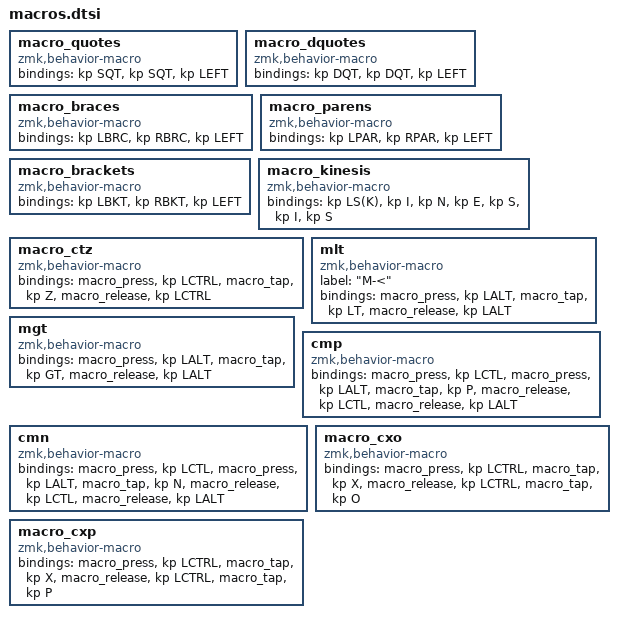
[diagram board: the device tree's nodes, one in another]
  macro_quotes: macro_quotes {
    compatible = "zmk,behavior-macro";
    #binding-cells = <0>;
    bindings = <&kp SQT>, <&kp SQT>, <&kp LEFT>;
  };
  macro_dquotes: macro_dquotes {
    compatible = "zmk,behavior-macro";
    #binding-cells = <0>;
    bindings = <&kp DQT>, <&kp DQT>, <&kp LEFT>;
  };
  macro_braces: macro_braces {
    compatible = "zmk,behavior-macro";
    #binding-cells = <0>;
    bindings = <&kp LBRC>, <&kp RBRC>, <&kp LEFT>;
  };
  macro_parens: macro_parens {
    compatible = "zmk,behavior-macro";
    #binding-cells = <0>;
    bindings = <&kp LPAR>, <&kp RPAR>, <&kp LEFT>;
  };
  macro_brackets: macro_brackets {
    compatible = "zmk,behavior-macro";
    #binding-cells = <0>;
    bindings = <&kp LBKT>, <&kp RBKT>, <&kp LEFT>;
  };
  macro_kinesis: macro_kinesis {
    compatible = "zmk,behavior-macro";
    #binding-cells = <0>;
    bindings = <&kp LS(K)>, <&kp I>, <&kp N>, <&kp E>, <&kp S>, <&kp I>, <&kp S>;
  };

macro_ctz: macro_ctz {
    compatible = "zmk,behavior-macro";
    #binding-cells = <0>;
    bindings
	= <&macro_press &kp LCTRL>
	, <&macro_tap &kp Z>
	, <&macro_release &kp LCTRL>
	;
};

mlt: mlt {
label = "M-<";
    compatible = "zmk,behavior-macro";
    #binding-cells = <0>;
    bindings
	= <&macro_press &kp LALT>
	, <&macro_tap &kp LT>
	, <&macro_release &kp LALT>
	;
};
mgt: mgt {
    compatible = "zmk,behavior-macro";
    #binding-cells = <0>;
    bindings
	= <&macro_press &kp LALT>
	, <&macro_tap &kp GT>
	, <&macro_release &kp LALT>
	;
};

cmp: cmp {
    compatible = "zmk,behavior-macro";
    #binding-cells = <0>;
    bindings
      = <&macro_press &kp LCTL>
      , <&macro_press &kp LALT>
      , <&macro_tap &kp P>
      , <&macro_release &kp LCTL>
      , <&macro_release &kp LALT>
      ;
};
cmn: cmn {
    compatible = "zmk,behavior-macro";
    #binding-cells = <0>;
    bindings
      = <&macro_press &kp LCTL>
      , <&macro_press &kp LALT>
      , <&macro_tap &kp N>
      , <&macro_release &kp LCTL>
      , <&macro_release &kp LALT>
      ;
};
macro_cxo: macro_cxo {
    compatible = "zmk,behavior-macro";
    #binding-cells = <0>;
    bindings
	= <&macro_press &kp LCTRL>
	, <&macro_tap &kp X>
	, <&macro_release &kp LCTRL>
        , <&macro_tap &kp O>
	;
};
macro_cxp: macro_cxp {
    compatible = "zmk,behavior-macro";
    #binding-cells = <0>;
    bindings
	= <&macro_press &kp LCTRL>
	, <&macro_tap &kp X>
	, <&macro_release &kp LCTRL>
        , <&macro_tap &kp P>
	;
};
